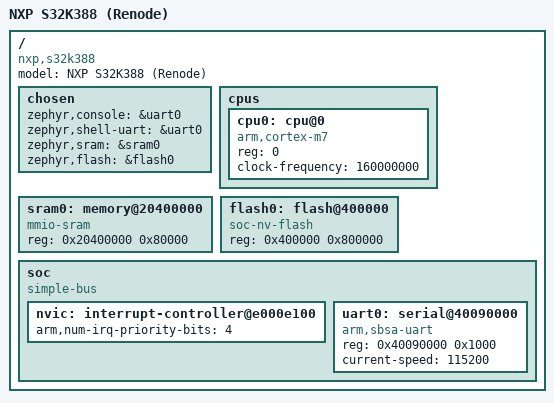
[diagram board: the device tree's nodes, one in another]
/*
 * Device tree for NXP S32K388 Renode simulation target.
 *
 * Minimal description: single Cortex-M7 core, 512KB SRAM, 8MB flash,
 * SBSA UART console.  Uses an ARM SBSA UART (simplified PL011 subset)
 * so that the Zephyr serial driver does not depend on the NXP HAL or
 * clock control.  Memory addresses match the custom Renode platform
 * file `zephyr/renode/s32k388_renode.repl`.
 *
 * Copyright (c) 2025 Vinicius Tadeu Zein
 * SPDX-License-Identifier: Apache-2.0
 */

/dts-v1/;
#include <arm/armv7-m.dtsi>

/ {
    model = "NXP S32K388 (Renode)";
    compatible = "nxp,s32k388";

    #address-cells = <1>;
    #size-cells = <1>;

    chosen {
        zephyr,console = &uart0;
        zephyr,shell-uart = &uart0;
        zephyr,sram = &sram0;
        zephyr,flash = &flash0;
    };

    cpus {
        #address-cells = <1>;
        #size-cells = <0>;

        cpu0: cpu@0 {
            device_type = "cpu";
            compatible = "arm,cortex-m7";
            reg = <0>;
            clock-frequency = <160000000>;
        };
    };

    sram0: memory@20400000 {
        compatible = "mmio-sram";
        reg = <0x20400000 0x80000>; /* 512KB */
    };

    flash0: flash@400000 {
        compatible = "soc-nv-flash";
        reg = <0x400000 0x800000>; /* 8MB */
    };

    soc {
        #address-cells = <1>;
        #size-cells = <1>;
        compatible = "simple-bus";
        ranges;

        nvic: interrupt-controller@e000e100 {
            arm,num-irq-priority-bits = <4>;
        };

        uart0: serial@40090000 {
            compatible = "arm,sbsa-uart";
            reg = <0x40090000 0x1000>;
            status = "okay";
            current-speed = <115200>;
        };
    };
};
